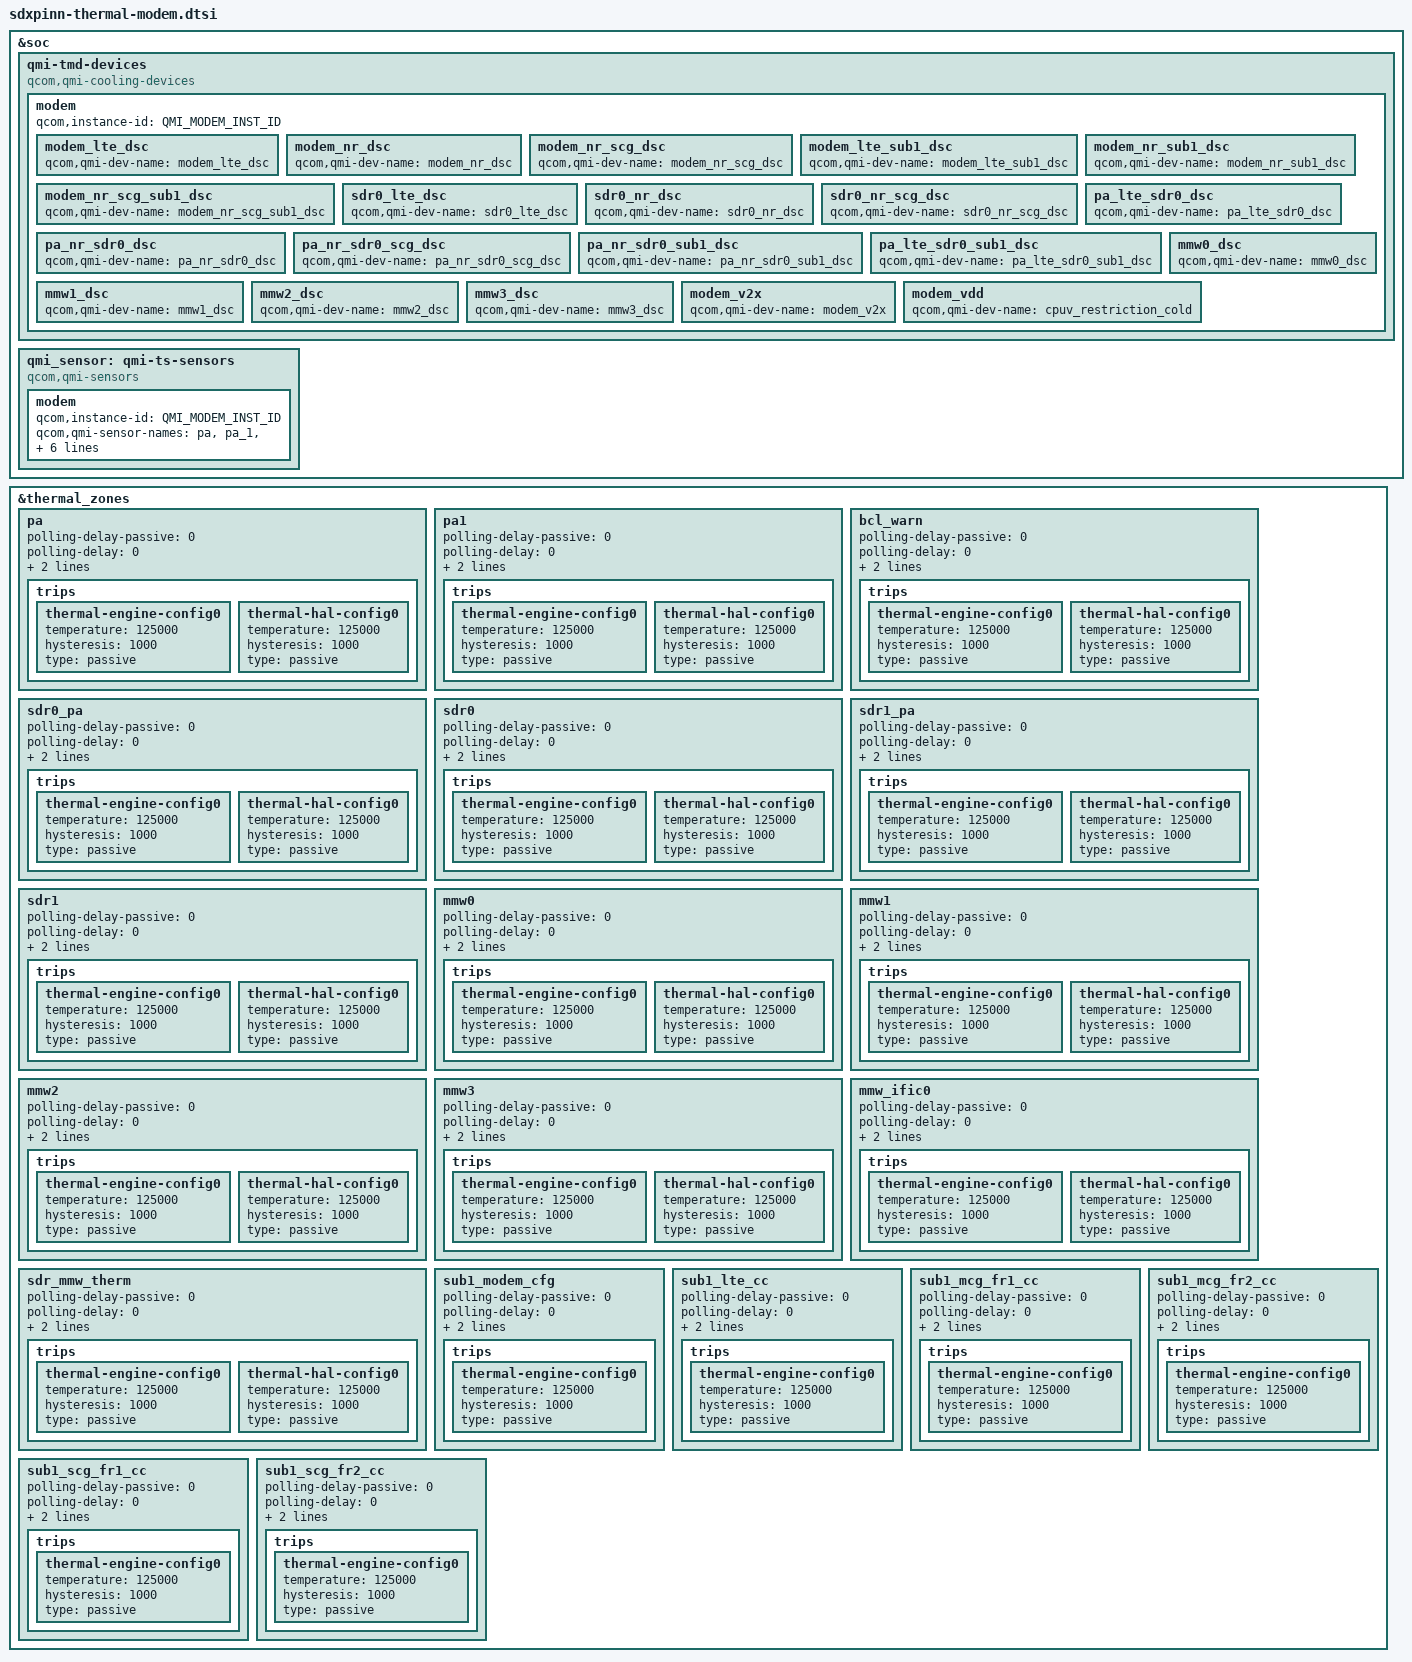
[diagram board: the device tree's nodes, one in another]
#include <dt-bindings/thermal/thermal_qti.h>

&soc {
	qmi-tmd-devices {
		compatible = "qcom,qmi-cooling-devices";

		modem {
			qcom,instance-id = <QMI_MODEM_INST_ID>;

			modem_lte_dsc: modem_lte_dsc {
				qcom,qmi-dev-name = "modem_lte_dsc";
				#cooling-cells = <2>;
			};

			modem_nr_dsc: modem_nr_dsc {
				qcom,qmi-dev-name = "modem_nr_dsc";
				#cooling-cells = <2>;
			};

			modem_nr_scg_dsc: modem_nr_scg_dsc {
				qcom,qmi-dev-name = "modem_nr_scg_dsc";
				#cooling-cells = <2>;
			};

			modem_lte_sub1_dsc: modem_lte_sub1_dsc {
				qcom,qmi-dev-name = "modem_lte_sub1_dsc";
				#cooling-cells = <2>;
			};

			modem_nr_sub1_dsc: modem_nr_sub1_dsc {
				qcom,qmi-dev-name = "modem_nr_sub1_dsc";
				#cooling-cells = <2>;
			};

			modem_nr_scg_sub1_dsc: modem_nr_scg_sub1_dsc {
				qcom,qmi-dev-name = "modem_nr_scg_sub1_dsc";
				#cooling-cells = <2>;
			};

			sdr0_lte_dsc: sdr0_lte_dsc {
				qcom,qmi-dev-name = "sdr0_lte_dsc";
				#cooling-cells = <2>;
			};

			sdr0_nr_dsc: sdr0_nr_dsc {
				qcom,qmi-dev-name = "sdr0_nr_dsc";
				#cooling-cells = <2>;
			};

			sdr0_nr_scg_dsc: sdr0_nr_scg_dsc {
				qcom,qmi-dev-name = "sdr0_nr_scg_dsc";
				#cooling-cells = <2>;
			};

			pa_lte_sdr0_dsc: pa_lte_sdr0_dsc {
				qcom,qmi-dev-name = "pa_lte_sdr0_dsc";
				#cooling-cells = <2>;
			};

			pa_nr_sdr0_dsc: pa_nr_sdr0_dsc {
				qcom,qmi-dev-name = "pa_nr_sdr0_dsc";
				#cooling-cells = <2>;
			};

			pa_nr_sdr0_scg_dsc: pa_nr_sdr0_scg_dsc {
				qcom,qmi-dev-name = "pa_nr_sdr0_scg_dsc";
				#cooling-cells = <2>;
			};

			pa_nr_sdr0_sub1_dsc: pa_nr_sdr0_sub1_dsc {
				qcom,qmi-dev-name = "pa_nr_sdr0_sub1_dsc";
				#cooling-cells = <2>;
			};

			pa_lte_sdr0_sub1_dsc: pa_lte_sdr0_sub1_dsc {
				qcom,qmi-dev-name = "pa_lte_sdr0_sub1_dsc";
				#cooling-cells = <2>;
			};

			mmw0_dsc: mmw0_dsc {
				qcom,qmi-dev-name = "mmw0_dsc";
				#cooling-cells = <2>;
			};

			mmw1_dsc: mmw1_dsc {
				qcom,qmi-dev-name = "mmw1_dsc";
				#cooling-cells = <2>;
			};

			mmw2_dsc: mmw2_dsc {
				qcom,qmi-dev-name = "mmw2_dsc";
				#cooling-cells = <2>;
			};

			mmw3_dsc: mmw3_dsc {
				qcom,qmi-dev-name = "mmw3_dsc";
				#cooling-cells = <2>;
			};

			modem_v2x: modem_v2x {
				qcom,qmi-dev-name = "modem_v2x";
				#cooling-cells = <2>;
			};

			modem_vdd: modem_vdd {
				qcom,qmi-dev-name = "cpuv_restriction_cold";
				#cooling-cells = <2>;
			};
		};
	};

	qmi_sensor: qmi-ts-sensors {
		compatible = "qcom,qmi-sensors";
		#thermal-sensor-cells = <1>;

		modem {
			qcom,instance-id = <QMI_MODEM_INST_ID>;
			qcom,qmi-sensor-names = "pa",
						"pa_1",
						"modem_bcl_warn",
						"sdr0",
						"sdr1",
						"sdr0_pa",
						"sdr1_pa",
						"mmw0",
						"mmw1",
						"mmw2",
						"mmw3",
						"mmw_ific0",
						"sub0_sdr0_pa",
						"sub1_sdr0_pa",
						"sdr_mmw_therm",
						"sub1_modem_cfg",
						"sub1_lte_cc",
						"sub1_mcg_fr1_cc",
						"sub1_mcg_fr2_cc",
						"sub1_scg_fr1_cc",
						"sub1_scg_fr2_cc";
		};
	};
};

&thermal_zones {
	pa {
		polling-delay-passive = <0>;
		polling-delay = <0>;
		thermal-sensors = <&qmi_sensor
				(QMI_MODEM_INST_ID+QMI_PA)>;
		trips {
			thermal-engine-config0 {
				temperature = <125000>;
				hysteresis = <1000>;
				type = "passive";
			};

			thermal-hal-config0 {
				temperature = <125000>;
				hysteresis = <1000>;
				type = "passive";
			};
		};
	};

	pa1 {
		polling-delay-passive = <0>;
		polling-delay = <0>;
		thermal-sensors = <&qmi_sensor
				(QMI_MODEM_INST_ID+QMI_PA_1)>;
		trips {
			thermal-engine-config0 {
				temperature = <125000>;
				hysteresis = <1000>;
				type = "passive";
			};

			thermal-hal-config0 {
				temperature = <125000>;
				hysteresis = <1000>;
				type = "passive";
			};
		};
	};

	bcl_warn {
		polling-delay-passive = <0>;
		polling-delay = <0>;
		thermal-sensors = <&qmi_sensor
				(QMI_MODEM_INST_ID+QMI_BCL_WARN)>;
		trips {
			thermal-engine-config0 {
				temperature = <125000>;
				hysteresis = <1000>;
				type = "passive";
			};

			thermal-hal-config0 {
				temperature = <125000>;
				hysteresis = <1000>;
				type = "passive";
			};
		};
	};

	sdr0_pa {
		polling-delay-passive = <0>;
		polling-delay = <0>;
		thermal-sensors = <&qmi_sensor
				(QMI_MODEM_INST_ID+QMI_SDR0_PA)>;
		trips {
			thermal-engine-config0 {
				temperature = <125000>;
				hysteresis = <1000>;
				type = "passive";
			};

			thermal-hal-config0 {
				temperature = <125000>;
				hysteresis = <1000>;
				type = "passive";
			};
		};
	};

	sdr0 {
		polling-delay-passive = <0>;
		polling-delay = <0>;
		thermal-sensors = <&qmi_sensor
				(QMI_MODEM_INST_ID+QMI_SDR0)>;
		trips {
			thermal-engine-config0 {
				temperature = <125000>;
				hysteresis = <1000>;
				type = "passive";
			};

			thermal-hal-config0 {
				temperature = <125000>;
				hysteresis = <1000>;
				type = "passive";
			};
		};
	};

	sdr1_pa {
		polling-delay-passive = <0>;
		polling-delay = <0>;
		thermal-sensors = <&qmi_sensor
				(QMI_MODEM_INST_ID+QMI_SDR1_PA)>;
		trips {
			thermal-engine-config0 {
				temperature = <125000>;
				hysteresis = <1000>;
				type = "passive";
			};

			thermal-hal-config0 {
				temperature = <125000>;
				hysteresis = <1000>;
				type = "passive";
			};
		};
	};

	sdr1 {
		polling-delay-passive = <0>;
		polling-delay = <0>;
		thermal-sensors = <&qmi_sensor
				(QMI_MODEM_INST_ID+QMI_SDR1)>;
		trips {
			thermal-engine-config0 {
				temperature = <125000>;
				hysteresis = <1000>;
				type = "passive";
			};

			thermal-hal-config0 {
				temperature = <125000>;
				hysteresis = <1000>;
				type = "passive";
			};
		};
	};

	mmw0 {
		polling-delay-passive = <0>;
		polling-delay = <0>;
		thermal-sensors = <&qmi_sensor
				(QMI_MODEM_INST_ID+QMI_MMW0)>;
		trips {
			thermal-engine-config0 {
				temperature = <125000>;
				hysteresis = <1000>;
				type = "passive";
			};

			thermal-hal-config0 {
				temperature = <125000>;
				hysteresis = <1000>;
				type = "passive";
			};
		};
	};

	mmw1 {
		polling-delay-passive = <0>;
		polling-delay = <0>;
		thermal-sensors = <&qmi_sensor
				(QMI_MODEM_INST_ID+QMI_MMW1)>;
		trips {
			thermal-engine-config0 {
				temperature = <125000>;
				hysteresis = <1000>;
				type = "passive";
			};

			thermal-hal-config0 {
				temperature = <125000>;
				hysteresis = <1000>;
				type = "passive";
			};
		};
	};

	mmw2 {
		polling-delay-passive = <0>;
		polling-delay = <0>;
		thermal-sensors = <&qmi_sensor
				(QMI_MODEM_INST_ID+QMI_MMW2)>;
		trips {
			thermal-engine-config0 {
				temperature = <125000>;
				hysteresis = <1000>;
				type = "passive";
			};

			thermal-hal-config0 {
				temperature = <125000>;
				hysteresis = <1000>;
				type = "passive";
			};
		};
	};

	mmw3 {
		polling-delay-passive = <0>;
		polling-delay = <0>;
		thermal-sensors = <&qmi_sensor
				(QMI_MODEM_INST_ID+QMI_MMW3)>;
		trips {
			thermal-engine-config0 {
				temperature = <125000>;
				hysteresis = <1000>;
				type = "passive";
			};

			thermal-hal-config0 {
				temperature = <125000>;
				hysteresis = <1000>;
				type = "passive";
			};
		};
	};

	mmw_ific0 {
		polling-delay-passive = <0>;
		polling-delay = <0>;
		thermal-sensors = <&qmi_sensor
				(QMI_MODEM_INST_ID+QMI_MMW_IFIC0)>;
		trips {
			thermal-engine-config0 {
				temperature = <125000>;
				hysteresis = <1000>;
				type = "passive";
			};

			thermal-hal-config0 {
				temperature = <125000>;
				hysteresis = <1000>;
				type = "passive";
			};
		};
	};

	sdr_mmw_therm {
		polling-delay-passive = <0>;
		polling-delay = <0>;
		thermal-sensors = <&qmi_sensor
				(QMI_MODEM_INST_ID+QMI_SDR_MMW)>;
		trips {
			thermal-engine-config0 {
				temperature = <125000>;
				hysteresis = <1000>;
				type = "passive";
			};

			thermal-hal-config0 {
				temperature = <125000>;
				hysteresis = <1000>;
				type = "passive";
			};
		};
	};

	sub1_modem_cfg {
		polling-delay-passive = <0>;
		polling-delay = <0>;
		thermal-sensors = <&qmi_sensor
				(QMI_MODEM_INST_ID+QMI_SUB1_MODEM_CFG)>;
		trips {
			thermal-engine-config0 {
				temperature = <125000>;
				hysteresis = <1000>;
				type = "passive";
			};
		};
	};

	sub1_lte_cc {
		polling-delay-passive = <0>;
		polling-delay = <0>;
		thermal-sensors = <&qmi_sensor
				(QMI_MODEM_INST_ID+QMI_SUB1_LTE_CC)>;
		trips {
			thermal-engine-config0 {
				temperature = <125000>;
				hysteresis = <1000>;
				type = "passive";
			};
		};
	};

	sub1_mcg_fr1_cc {
		polling-delay-passive = <0>;
		polling-delay = <0>;
		thermal-sensors = <&qmi_sensor
				(QMI_MODEM_INST_ID+QMI_SUB1_MCG_FR1_CC)>;
		trips {
			thermal-engine-config0 {
				temperature = <125000>;
				hysteresis = <1000>;
				type = "passive";
			};
		};
	};

	sub1_mcg_fr2_cc {
		polling-delay-passive = <0>;
		polling-delay = <0>;
		thermal-sensors = <&qmi_sensor
				(QMI_MODEM_INST_ID+QMI_SUB1_MCG_FR2_CC)>;
		trips {
			thermal-engine-config0 {
				temperature = <125000>;
				hysteresis = <1000>;
				type = "passive";
			};
		};
	};

	sub1_scg_fr1_cc {
		polling-delay-passive = <0>;
		polling-delay = <0>;
		thermal-sensors = <&qmi_sensor
				(QMI_MODEM_INST_ID+QMI_SUB1_SCG_FR1_CC)>;
		trips {
			thermal-engine-config0 {
				temperature = <125000>;
				hysteresis = <1000>;
				type = "passive";
			};
		};
	};

	sub1_scg_fr2_cc {
		polling-delay-passive = <0>;
		polling-delay = <0>;
		thermal-sensors = <&qmi_sensor
				(QMI_MODEM_INST_ID+QMI_SUB1_SCG_FR2_CC)>;
		trips {
			thermal-engine-config0 {
				temperature = <125000>;
				hysteresis = <1000>;
				type = "passive";
			};
		};
	};
};
